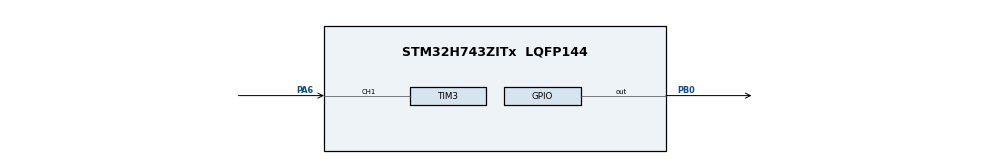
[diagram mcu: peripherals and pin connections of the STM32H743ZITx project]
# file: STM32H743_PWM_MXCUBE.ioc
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Mcu.Family=STM32H7
Mcu.Name=STM32H743ZITx
Mcu.Package=LQFP144
NVIC.PriorityGroup=NVIC_PRIORITYGROUP_4
NVIC.TIM3_IRQn=true\:0\:0\:false\:false\:true\:true
PA13\ (JTMS/SWDIO).Mode=Trace_Asynchronous_SW
PA13\ (JTMS/SWDIO).Signal=SYS_JTMS-SWDIO
PA14\ (JTCK/SWCLK).Mode=Trace_Asynchronous_SW
PA14\ (JTCK/SWCLK).Signal=SYS_JTCK-SWCLK
PA6.Signal=S_TIM3_CH1
PB0.GPIO_Speed=GPIO_SPEED_FREQ_VERY_HIGH
PB0.Signal=GPIO_Output
PB3\ (JTDO/TRACESWO).Mode=Trace_Asynchronous_SW
PB3\ (JTDO/TRACESWO).Signal=SYS_JTDO-SWO
PC14-OSC32_IN\ (OSC32_IN).Mode=LSE-External-Oscillator
PC14-OSC32_IN\ (OSC32_IN).Signal=RCC_OSC32_IN
PC15-OSC32_OUT\ (OSC32_OUT).Mode=LSE-External-Oscillator
PC15-OSC32_OUT\ (OSC32_OUT).Signal=RCC_OSC32_OUT
PH0-OSC_IN\ (PH0).Mode=HSE-External-Oscillator
PH0-OSC_IN\ (PH0).Signal=RCC_OSC_IN
PH1-OSC_OUT\ (PH1).Mode=HSE-External-Oscillator
PH1-OSC_OUT\ (PH1).Signal=RCC_OSC_OUT
ProjectManager.HeapSize=0x2000
ProjectManager.StackSize=0x4000
ProjectManager.TargetToolchain=EWARM
RCC.ADCFreq_Value=129000000
RCC.APB1Freq_Value=96000000
RCC.APB2Freq_Value=96000000
RCC.APB3Freq_Value=96000000
RCC.APB4Freq_Value=96000000
RCC.CortexFreq_Value=384000000
RCC.D1PPRE=RCC_APB3_DIV2
RCC.D2PPRE1=RCC_APB1_DIV2
RCC.D2PPRE2=RCC_APB2_DIV2
RCC.D3PPRE=RCC_APB4_DIV2
RCC.DIVM1=16
RCC.DIVN1=192
RCC.HCLKFreq_Value=192000000
RCC.HPRE=RCC_HCLK_DIV2
RCC.HSE_VALUE=8000000
RCC.SYSCLKFreq_VALUE=384000000
RCC.SYSCLKSource=RCC_SYSCLKSOURCE_PLLCLK
RCC.USBFreq_Value=384000000
SH.S_TIM3_CH1.0=TIM3_CH1,Input_Capture1_from_TI1
TIM3.AutoReloadPreload=TIM_AUTORELOAD_PRELOAD_ENABLE
TIM3.Channel-Input_Capture1_from_TI1=TIM_CHANNEL_1
TIM3.ClockDivision=TIM_CLOCKDIVISION_DIV1
TIM3.Period=10000
TIM3.Prescaler=19199
VP_TIM3_VS_ClockSourceINT.Mode=Internal
board=custom

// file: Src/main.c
/**
  ******************************************************************************
  * @file           : main.c
  * @brief          : Main program body
  ******************************************************************************
  ** This notice applies to any and all portions of this file
  * that are not between comment pairs USER CODE BEGIN and
  * USER CODE END. Other portions of this file, whether
  * inserted by the user or by software development tools
  * are owned by their respective copyright owners.
  *
  * COPYRIGHT(c) 2020 STMicroelectronics
  *
  * Redistribution and use in source and binary forms, with or without modification,
  * are permitted provided that the following conditions are met:
  *   1. Redistributions of source code must retain the above copyright notice,
  *      this list of conditions and the following disclaimer.
  *   2. Redistributions in binary form must reproduce the above copyright notice,
  *      this list of conditions and the following disclaimer in the documentation
  *      and/or other materials provided with the distribution.
  *   3. Neither the name of STMicroelectronics nor the names of its contributors
  *      may be used to endorse or promote products derived from this software
  *      without specific prior written permission.
  *
  * THIS SOFTWARE IS PROVIDED BY THE COPYRIGHT HOLDERS AND CONTRIBUTORS "AS IS"
  * AND ANY EXPRESS OR IMPLIED WARRANTIES, INCLUDING, BUT NOT LIMITED TO, THE
  * IMPLIED WARRANTIES OF MERCHANTABILITY AND FITNESS FOR A PARTICULAR PURPOSE ARE
  * DISCLAIMED. IN NO EVENT SHALL THE COPYRIGHT HOLDER OR CONTRIBUTORS BE LIABLE
  * FOR ANY DIRECT, INDIRECT, INCIDENTAL, SPECIAL, EXEMPLARY, OR CONSEQUENTIAL
  * DAMAGES (INCLUDING, BUT NOT LIMITED TO, PROCUREMENT OF SUBSTITUTE GOODS OR
  * SERVICES; LOSS OF USE, DATA, OR PROFITS; OR BUSINESS INTERRUPTION) HOWEVER
  * CAUSED AND ON ANY THEORY OF LIABILITY, WHETHER IN CONTRACT, STRICT LIABILITY,
  * OR TORT (INCLUDING NEGLIGENCE OR OTHERWISE) ARISING IN ANY WAY OUT OF THE USE
  * OF THIS SOFTWARE, EVEN IF ADVISED OF THE POSSIBILITY OF SUCH DAMAGE.
  *
  ******************************************************************************
  */
#include "main.h"
#include "stm32h7xx_hal.h"
#include "tim.h"
#include "gpio.h"

/* USER CODE BEGIN PV */
/* Private variables ---------------------------------------------------------*/

/* USER CODE END PV */

void SystemClock_Config(void);

/* USER CODE BEGIN PFP */
/* Private function prototypes -----------------------------------------------*/

/* USER CODE END PFP */

int main(void)
{

  /* MCU Configuration----------------------------------------------------------*/

  /* Reset of all peripherals, Initializes the Flash interface and the Systick. */
  HAL_Init();

  /* Configure the system clock */
  SystemClock_Config();

  /* Initialize all configured peripherals */
  MX_GPIO_Init();
  MX_TIM3_Init();
  /* USER CODE BEGIN 2 */
	if (HAL_TIM_Base_Start_IT(&htim3) !=HAL_OK)
	{
		_Error_Handler(__FILE__, __LINE__);
	}

  /* USER CODE END 2 */

  /* Infinite loop */
  while (1)
  {

  }

}

void SystemClock_Config(void)
{

  RCC_OscInitTypeDef RCC_OscInitStruct;
  RCC_ClkInitTypeDef RCC_ClkInitStruct;

    /**Supply configuration update enable
    */
  MODIFY_REG(PWR->CR3, PWR_CR3_SCUEN, 0);

    /**Configure the main internal regulator output voltage
    */
  __HAL_PWR_VOLTAGESCALING_CONFIG(PWR_REGULATOR_VOLTAGE_SCALE1);

  while ((PWR->D3CR & (PWR_D3CR_VOSRDY)) != PWR_D3CR_VOSRDY)
  {

  }
    /**Initializes the CPU, AHB and APB busses clocks
    */
  RCC_OscInitStruct.OscillatorType = RCC_OSCILLATORTYPE_HSI;
  RCC_OscInitStruct.HSIState = RCC_HSI_DIV1;
  RCC_OscInitStruct.HSICalibrationValue = 16;
  RCC_OscInitStruct.PLL.PLLState = RCC_PLL_ON;
  RCC_OscInitStruct.PLL.PLLSource = RCC_PLLSOURCE_HSI;
  RCC_OscInitStruct.PLL.PLLM = 16;
  RCC_OscInitStruct.PLL.PLLN = 192;
  RCC_OscInitStruct.PLL.PLLP = 2;
  RCC_OscInitStruct.PLL.PLLQ = 2;
  RCC_OscInitStruct.PLL.PLLR = 2;
  RCC_OscInitStruct.PLL.PLLRGE = RCC_PLL1VCIRANGE_2;
  RCC_OscInitStruct.PLL.PLLVCOSEL = RCC_PLL1VCOWIDE;
  RCC_OscInitStruct.PLL.PLLFRACN = 0;
  if (HAL_RCC_OscConfig(&RCC_OscInitStruct) != HAL_OK)
  {
    _Error_Handler(__FILE__, __LINE__);
  }

    /**Initializes the CPU, AHB and APB busses clocks
    */
  RCC_ClkInitStruct.ClockType = RCC_CLOCKTYPE_HCLK|RCC_CLOCKTYPE_SYSCLK
                              |RCC_CLOCKTYPE_PCLK1|RCC_CLOCKTYPE_PCLK2
                              |RCC_CLOCKTYPE_D3PCLK1|RCC_CLOCKTYPE_D1PCLK1;
  RCC_ClkInitStruct.SYSCLKSource = RCC_SYSCLKSOURCE_PLLCLK;
  RCC_ClkInitStruct.SYSCLKDivider = RCC_SYSCLK_DIV1;
  RCC_ClkInitStruct.AHBCLKDivider = RCC_HCLK_DIV2;
  RCC_ClkInitStruct.APB3CLKDivider = RCC_APB3_DIV2;
  RCC_ClkInitStruct.APB1CLKDivider = RCC_APB1_DIV2;
  RCC_ClkInitStruct.APB2CLKDivider = RCC_APB2_DIV2;
  RCC_ClkInitStruct.APB4CLKDivider = RCC_APB4_DIV2;

  if (HAL_RCC_ClockConfig(&RCC_ClkInitStruct, FLASH_LATENCY_2) != HAL_OK)
  {
    _Error_Handler(__FILE__, __LINE__);
  }

    /**Configure the Systick interrupt time
    */
  HAL_SYSTICK_Config(SystemCoreClock/1000);

    /**Configure the Systick
    */
  HAL_SYSTICK_CLKSourceConfig(SYSTICK_CLKSOURCE_HCLK);

  /* SysTick_IRQn interrupt configuration */
  HAL_NVIC_SetPriority(SysTick_IRQn, 0, 0);
}

/* USER CODE BEGIN 4 */
/**
  * @brief  Period elapsed callback in non blocking mode
  * @param  htim : TIM handle
  * @retval None
  */
void HAL_TIM_PeriodElapsedCallback(TIM_HandleTypeDef *htim)
{
	HAL_GPIO_TogglePin(GPIOB, GPIO_PIN_0);
}
/* USER CODE END 4 */

void _Error_Handler(char *file, int line)
{
  while(1)
  {
  }
}

/************************ (C) COPYRIGHT STMicroelectronics *****END OF FILE****/
